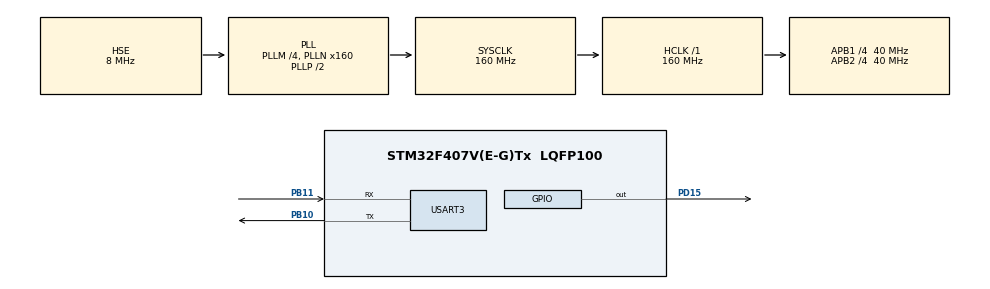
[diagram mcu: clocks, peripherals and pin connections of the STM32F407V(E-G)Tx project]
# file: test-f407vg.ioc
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Mcu.Family=STM32F4
Mcu.Name=STM32F407V(E-G)Tx
Mcu.Package=LQFP100
NVIC.PriorityGroup=NVIC_PRIORITYGROUP_4
NVIC.RTC_WKUP_IRQn=true\:1\:0\:true\:false\:true\:true\:true
PA13.Mode=Serial_Wire
PA13.Signal=SYS_JTMS-SWDIO
PA14.Mode=Serial_Wire
PA14.Signal=SYS_JTCK-SWCLK
PB10.Mode=Asynchronous
PB10.Signal=USART3_TX
PB11.Mode=Asynchronous
PB11.Signal=USART3_RX
PD15.Signal=GPIO_Output
PH0-OSC_IN.Mode=HSE-External-Oscillator
PH0-OSC_IN.Signal=RCC_OSC_IN
PH1-OSC_OUT.Mode=HSE-External-Oscillator
PH1-OSC_OUT.Signal=RCC_OSC_OUT
ProjectManager.HeapSize=0x200
ProjectManager.StackSize=0x400
ProjectManager.TargetToolchain=Makefile
RCC.48MHZClocksFreq_Value=80000000
RCC.AHBFreq_Value=160000000
RCC.APB1CLKDivider=RCC_HCLK_DIV4
RCC.APB1Freq_Value=40000000
RCC.APB1TimFreq_Value=80000000
RCC.APB2CLKDivider=RCC_HCLK_DIV4
RCC.APB2Freq_Value=40000000
RCC.APB2TimFreq_Value=80000000
RCC.CortexFreq_Value=160000000
RCC.HCLKFreq_Value=160000000
RCC.HSE_VALUE=8000000
RCC.HSI_VALUE=16000000
RCC.LSE_VALUE=32768
RCC.PLLM=4
RCC.PLLN=160
RCC.PLLSourceVirtual=RCC_PLLSOURCE_HSE
RCC.SYSCLKFreq_VALUE=160000000
RCC.SYSCLKSource=RCC_SYSCLKSOURCE_PLLCLK
RCC.VCOOutputFreq_Value=320000000
RTC.Format=RTC_FORMAT_BIN
RTC.WakeUpClock=RTC_WAKEUPCLOCK_CK_SPRE_16BITS
USART3.VirtualMode=VM_ASYNC
VP_RTC_VS_RTC_Activate.Mode=RTC_Enabled
VP_RTC_VS_RTC_WakeUp_intern.Mode=WakeUp
board=custom

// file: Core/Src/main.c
/* USER CODE BEGIN Header */
/**
   ******************************************************************************
  * @file           : main.c
  * @brief          : Main program body
  ******************************************************************************
  * @attention
  *
  * <h2><center>&copy; Copyright (c) 2021 STMicroelectronics.
  * All rights reserved.</center></h2>
  *
  * This software component is licensed by ST under BSD 3-Clause license,
  * the "License"; You may not use this file except in compliance with the
  * License. You may obtain a copy of the License at:
  *                        opensource.org/licenses/BSD-3-Clause
  *
  ******************************************************************************
  */
/* USER CODE END Header */
#include "main.h"

/* USER CODE BEGIN Includes */
#include <stdio.h>
#include <stdlib.h>
/* USER CODE END Includes */

RTC_HandleTypeDef hrtc;

UART_HandleTypeDef huart3;

void SystemClock_Config(void);
static void MX_GPIO_Init(void);
static void MX_RTC_Init(void);
static void MX_USART3_UART_Init(void);

/* USER CODE BEGIN 0 */
// Some functions for printing ower SWO (debug only)
void SWO_PrintChar(char const c, uint8_t const portNo)
{
    volatile int timeout;

    /* Check if Trace Control Register (ITM->TCR at 0xE0000E80) is set */
    /* check Trace Control Register if ITM trace is enabled*/
    if ((ITM->TCR & ITM_TCR_ITMENA_Msk) == 0)
    {
        return; /* not enabled? */
    }
    /* Check if the requested channel stimulus port (ITM->TER at 0xE0000E00) is enabled */
    /* check Trace Enable Register if requested port is enabled */
    if ((ITM->TER & (1ul << portNo)) == 0)
    {
        return; /* requested port not enabled? */
    }
    timeout = 5000; /* arbitrary timeout value */
    while (ITM->PORT[0].u32 == 0)
    {
        /* Wait until STIMx is ready, then send data */
        if (--timeout == 0)
        {
            return; /* not able to send */
        }
    }
    ITM->PORT[0].u8 = (uint8_t)c;
}
void SWO_PrintString(char const* s, uint8_t const portNumber)
{
    while (*s != '\0')
    {
        SWO_PrintChar(*s++, portNumber);
    }
}
void printString(char const* str)
{
    SWO_PrintString(str, 0);
}

// This circus is for demonstrating compiler optimizations
void f1();
void f2();
void f3();

// RTC will trigger every second, toggel LED and print message over SWO
void HAL_RTCEx_WakeUpTimerEventCallback(RTC_HandleTypeDef* hrtc)
{
  char str[] = "Hello";
  f1();
}

void f1()
{
  char c = 'c';
  f2();
}

void f2()
{
  static uint8_t dummy;
  dummy++;
  f3();
}

void f3()
{
    char msg[20];
    static uint32_t counter = 0;
    size_t const len = sprintf(msg, "Counter = %lu\n\r", counter++);
    printString(msg);
    HAL_UART_Transmit(&huart3, (uint8_t*)msg, len, 10);
    HAL_GPIO_TogglePin(GPIOD, GPIO_PIN_15);
}

/* USER CODE END 0 */

int main(void)
{

  /* MCU Configuration--------------------------------------------------------*/

  /* Reset of all peripherals, Initializes the Flash interface and the Systick. */
  HAL_Init();

  /* Configure the system clock */
  SystemClock_Config();

  /* Initialize all configured peripherals */
  MX_GPIO_Init();
  MX_RTC_Init();
  MX_USART3_UART_Init();
  /* USER CODE BEGIN 2 */

    // Empty variables to show compiler option -Wno-unused-variable and optimizations
    int var1 = 549;
    float var2 = 24.241f;
    char var3 = 'c';
    double var4 = 521.521;

  /* USER CODE END 2 */

  /* Infinite loop */
  /* USER CODE BEGIN WHILE */
    while (1)
    {
      ++var1;
      var3 = var3 != 'C' ? 'C' : 'c';
      var4 += (float)(rand()%10) / (float)(rand() % 1000);

    /* USER CODE END WHILE */

    }
}

void SystemClock_Config(void)
{
  RCC_OscInitTypeDef RCC_OscInitStruct = {0};
  RCC_ClkInitTypeDef RCC_ClkInitStruct = {0};
  RCC_PeriphCLKInitTypeDef PeriphClkInitStruct = {0};

  /** Configure the main internal regulator output voltage
  */
  __HAL_RCC_PWR_CLK_ENABLE();
  __HAL_PWR_VOLTAGESCALING_CONFIG(PWR_REGULATOR_VOLTAGE_SCALE1);
  /** Initializes the RCC Oscillators according to the specified parameters
  * in the RCC_OscInitTypeDef structure.
  */
  RCC_OscInitStruct.OscillatorType = RCC_OSCILLATORTYPE_LSI|RCC_OSCILLATORTYPE_HSE;
  RCC_OscInitStruct.HSEState = RCC_HSE_ON;
  RCC_OscInitStruct.LSIState = RCC_LSI_ON;
  RCC_OscInitStruct.PLL.PLLState = RCC_PLL_ON;
  RCC_OscInitStruct.PLL.PLLSource = RCC_PLLSOURCE_HSE;
  RCC_OscInitStruct.PLL.PLLM = 4;
  RCC_OscInitStruct.PLL.PLLN = 160;
  RCC_OscInitStruct.PLL.PLLP = RCC_PLLP_DIV2;
  RCC_OscInitStruct.PLL.PLLQ = 4;
  if (HAL_RCC_OscConfig(&RCC_OscInitStruct) != HAL_OK)
  {
    Error_Handler();
  }
  /** Initializes the CPU, AHB and APB buses clocks
  */
  RCC_ClkInitStruct.ClockType = RCC_CLOCKTYPE_HCLK|RCC_CLOCKTYPE_SYSCLK
                              |RCC_CLOCKTYPE_PCLK1|RCC_CLOCKTYPE_PCLK2;
  RCC_ClkInitStruct.SYSCLKSource = RCC_SYSCLKSOURCE_PLLCLK;
  RCC_ClkInitStruct.AHBCLKDivider = RCC_SYSCLK_DIV1;
  RCC_ClkInitStruct.APB1CLKDivider = RCC_HCLK_DIV4;
  RCC_ClkInitStruct.APB2CLKDivider = RCC_HCLK_DIV4;

  if (HAL_RCC_ClockConfig(&RCC_ClkInitStruct, FLASH_LATENCY_5) != HAL_OK)
  {
    Error_Handler();
  }
  PeriphClkInitStruct.PeriphClockSelection = RCC_PERIPHCLK_RTC;
  PeriphClkInitStruct.RTCClockSelection = RCC_RTCCLKSOURCE_LSI;
  if (HAL_RCCEx_PeriphCLKConfig(&PeriphClkInitStruct) != HAL_OK)
  {
    Error_Handler();
  }
}

static void MX_RTC_Init(void)
{

  RTC_TimeTypeDef sTime = {0};
  RTC_DateTypeDef sDate = {0};

  /** Initialize RTC Only
  */
  hrtc.Instance = RTC;
  hrtc.Init.HourFormat = RTC_HOURFORMAT_24;
  hrtc.Init.AsynchPrediv = 127;
  hrtc.Init.SynchPrediv = 255;
  hrtc.Init.OutPut = RTC_OUTPUT_DISABLE;
  hrtc.Init.OutPutPolarity = RTC_OUTPUT_POLARITY_HIGH;
  hrtc.Init.OutPutType = RTC_OUTPUT_TYPE_OPENDRAIN;
  if (HAL_RTC_Init(&hrtc) != HAL_OK)
  {
    Error_Handler();
  }

  /** Initialize RTC and set the Time and Date
  */
  sTime.Hours = 0;
  sTime.Minutes = 0;
  sTime.Seconds = 0;
  sTime.DayLightSaving = RTC_DAYLIGHTSAVING_NONE;
  sTime.StoreOperation = RTC_STOREOPERATION_RESET;
  if (HAL_RTC_SetTime(&hrtc, &sTime, RTC_FORMAT_BIN) != HAL_OK)
  {
    Error_Handler();
  }
  sDate.WeekDay = RTC_WEEKDAY_MONDAY;
  sDate.Month = RTC_MONTH_JANUARY;
  sDate.Date = 1;
  sDate.Year = 0;

  if (HAL_RTC_SetDate(&hrtc, &sDate, RTC_FORMAT_BIN) != HAL_OK)
  {
    Error_Handler();
  }
  /** Enable the WakeUp
  */
  if (HAL_RTCEx_SetWakeUpTimer_IT(&hrtc, 0, RTC_WAKEUPCLOCK_CK_SPRE_16BITS) != HAL_OK)
  {
    Error_Handler();
  }

}

static void MX_USART3_UART_Init(void)
{

  huart3.Instance = USART3;
  huart3.Init.BaudRate = 115200;
  huart3.Init.WordLength = UART_WORDLENGTH_8B;
  huart3.Init.StopBits = UART_STOPBITS_1;
  huart3.Init.Parity = UART_PARITY_NONE;
  huart3.Init.Mode = UART_MODE_TX_RX;
  huart3.Init.HwFlowCtl = UART_HWCONTROL_NONE;
  huart3.Init.OverSampling = UART_OVERSAMPLING_16;
  if (HAL_UART_Init(&huart3) != HAL_OK)
  {
    Error_Handler();
  }

}

static void MX_GPIO_Init(void)
{
  GPIO_InitTypeDef GPIO_InitStruct = {0};

  /* GPIO Ports Clock Enable */
  __HAL_RCC_GPIOH_CLK_ENABLE();
  __HAL_RCC_GPIOB_CLK_ENABLE();
  __HAL_RCC_GPIOD_CLK_ENABLE();
  __HAL_RCC_GPIOA_CLK_ENABLE();

  /*Configure GPIO pin Output Level */
  HAL_GPIO_WritePin(GPIOD, GPIO_PIN_15, GPIO_PIN_RESET);

  /*Configure GPIO pin : PD15 */
  GPIO_InitStruct.Pin = GPIO_PIN_15;
  GPIO_InitStruct.Mode = GPIO_MODE_OUTPUT_PP;
  GPIO_InitStruct.Pull = GPIO_NOPULL;
  GPIO_InitStruct.Speed = GPIO_SPEED_FREQ_LOW;
  HAL_GPIO_Init(GPIOD, &GPIO_InitStruct);

}

void Error_Handler(void)
{
    __disable_irq();
    while (1)
    {
    }
}

/************************ (C) COPYRIGHT STMicroelectronics *****END OF FILE****/
